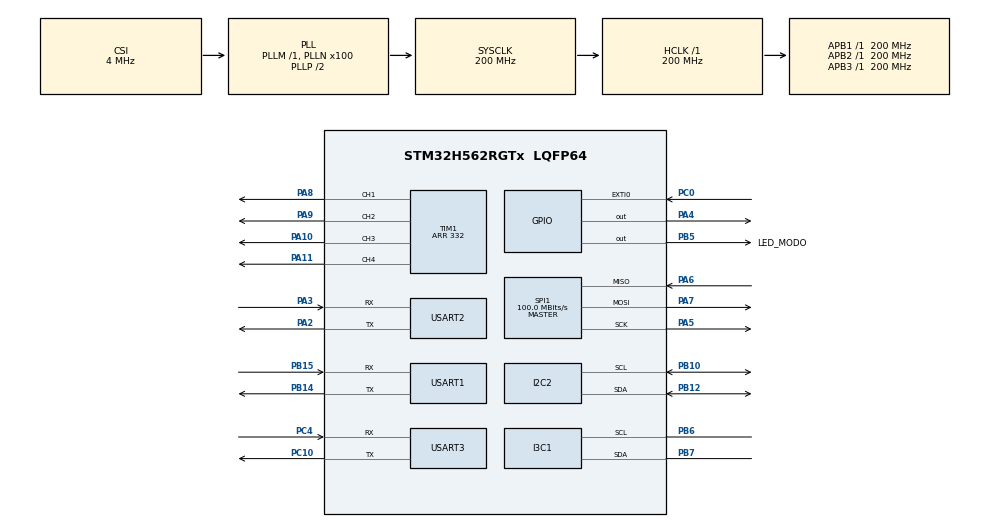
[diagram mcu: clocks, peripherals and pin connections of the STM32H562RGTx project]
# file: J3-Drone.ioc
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BOOTPATH.BootPathName=LEGACY
BOOTPATH.UserSelectedBootPath=LEGACY
CORTEX_M33_NS.Number-Cortex_Memory_Protection_Unit_Region0_OTP_RO_AREAS_Settings=MPU_REGION_NUMBER0
CORTEX_M33_NS.default_mode_Activation=1
CORTEX_M33_NS.userName=CORTEX_M33
I2C2.Timing=0x30C0EDFF
I3C1.BusFreeDuration=403
I3C1.Register0=0x005f3f5f
I3C1.Register1=0x002700c6
I3C1.SCLI3CHighDuration=0x3f
I3C1.SCLODLowDuration=0x5f
I3C1.SCLPPLowDuration=0x5f
I3C1.SCL_OD_Freq=1250
I3C1.SCL_PP_Freq=1250
I3C1.hexBusFreeDuration=0x27
I3C1.hexBusIdleDuration=0xc6
Mcu.Family=STM32H5
Mcu.Name=STM32H562RGTx
Mcu.Package=LQFP64
NVIC.EXTI0_IRQn=true\:5\:0\:false\:false\:true\:true\:false\:false
NVIC.PriorityGroup=NVIC_PRIORITYGROUP_4
NVIC.USART2_IRQn=true\:0\:0\:false\:false\:true\:true\:true\:true
PA10.Signal=S_TIM1_CH3
PA11.Signal=S_TIM1_CH4
PA13(JTMS/SWDIO).Mode=Serial_Wire
PA13(JTMS/SWDIO).Signal=DEBUG_JTMS-SWDIO
PA14(JTCK/SWCLK).Mode=Serial_Wire
PA14(JTCK/SWCLK).Signal=DEBUG_JTCK-SWCLK
PA2.Mode=Asynchronous
PA2.Signal=USART2_TX
PA3.Mode=Asynchronous
PA3.Signal=USART2_RX
PA4.Signal=GPIO_Output
PA5.Mode=Full_Duplex_Master
PA5.Signal=SPI1_SCK
PA6.Mode=Full_Duplex_Master
PA6.Signal=SPI1_MISO
PA7.Mode=Full_Duplex_Master
PA7.Signal=SPI1_MOSI
PA8.Signal=S_TIM1_CH1
PA9.Signal=S_TIM1_CH2
PB10.Mode=I2C
PB10.Signal=I2C2_SCL
PB12.Mode=I2C
PB12.Signal=I2C2_SDA
PB14.Mode=Asynchronous
PB14.Signal=USART1_TX
PB15.Mode=Asynchronous
PB15.Signal=USART1_RX
PB5.GPIO_Label=LED_MODO
PB5.Signal=GPIO_Output
PB6.Mode=Controller
PB6.Signal=I3C1_SCL
PB7.Mode=Controller
PB7.Signal=I3C1_SDA
PC0.Signal=GPXTI0
PC10.Mode=Asynchronous
PC10.Signal=USART3_TX
PC14-OSC32_IN(OSC32_IN).Mode=LSE-External-Oscillator
PC14-OSC32_IN(OSC32_IN).Signal=RCC_OSC32_IN
PC15-OSC32_OUT(OSC32_OUT).Mode=LSE-External-Oscillator
PC15-OSC32_OUT(OSC32_OUT).Signal=RCC_OSC32_OUT
PC4.Mode=Asynchronous
PC4.Signal=USART3_RX
PH0-OSC_IN(PH0).Mode=HSE-External-Oscillator
PH0-OSC_IN(PH0).Signal=RCC_OSC_IN
PH1-OSC_OUT(PH1).Mode=HSE-External-Oscillator
PH1-OSC_OUT(PH1).Signal=RCC_OSC_OUT
ProjectManager.HeapSize=0x200
ProjectManager.StackSize=0x400
ProjectManager.TargetToolchain=CMake
RCC.ADCFreq_Value=200000000
RCC.AHBFreq_Value=200000000
RCC.APB1Freq_Value=200000000
RCC.APB1TimFreq_Value=200000000
RCC.APB2Freq_Value=200000000
RCC.APB2TimFreq_Value=200000000
RCC.APB3Freq_Value=200000000
RCC.CSI_VALUE=4000000
RCC.CortexFreq_Value=200000000
RCC.EPOD_VALUE=4000000
RCC.HCLKFreq_Value=200000000
RCC.HSE_VALUE=25000000
RCC.HSI48_VALUE=48000000
RCC.HSI_VALUE=64000000
RCC.LSIRC_VALUE=32000
RCC.PLL2FRACN=0
RCC.PLL2M=1
RCC.PLL2N=96
RCC.PLL2P=8
RCC.PLL2Q=2
RCC.PLL2R=2
RCC.PLL2RGE=RCC_PLL2_VCIRANGE_2
RCC.PLL2State=RCC_PLL2_ON
RCC.PLL2VCOSEL=RCC_PLL2_VCORANGE_WIDE
RCC.PLL3FRACN=0
RCC.PLLFRACN=0
RCC.PLLN=100
RCC.SYSCLKFreq_VALUE=200000000
RCC.SYSCLKSource=RCC_SYSCLKSOURCE_PLLCLK
RCC.USBFreq_Value=48000000
RCC.VCOOutputFreq_Value=400000000
SH.S_TIM1_CH1.0=TIM1_CH1,PWM Generation1 CH1
SH.S_TIM1_CH2.0=TIM1_CH2,PWM Generation2 CH2
SH.S_TIM1_CH3.0=TIM1_CH3,PWM Generation3 CH3
SH.S_TIM1_CH4.0=TIM1_CH4,PWM Generation4 CH4
SPI1.BaudRatePrescaler=SPI_BAUDRATEPRESCALER_2
SPI1.CLKPhase=SPI_PHASE_1EDGE
SPI1.CLKPolarity=SPI_POLARITY_LOW
SPI1.CalculateBaudRate=100.0 MBits/s
SPI1.DataSize=SPI_DATASIZE_8BIT
SPI1.Direction=SPI_DIRECTION_2LINES
SPI1.FirstBit=SPI_FIRSTBIT_MSB
SPI1.Mode=SPI_MODE_MASTER
SPI1.NSS=SPI_NSS_SOFT
SPI1.NSSPMode=SPI_NSS_PULSE_DISABLE
SPI1.VirtualType=VM_MASTER
TIM1.Channel-PWM\ Generation1\ CH1=TIM_CHANNEL_1
TIM1.Channel-PWM\ Generation2\ CH2=TIM_CHANNEL_2
TIM1.Channel-PWM\ Generation3\ CH3=TIM_CHANNEL_3
TIM1.Channel-PWM\ Generation4\ CH4=TIM_CHANNEL_4
TIM1.PeriodNoDither=332
USART1.VirtualMode-Asynchronous=VM_ASYNC
USART2.VirtualMode-Asynchronous=VM_ASYNC
USART3.VirtualMode-Asynchronous=VM_ASYNC
VP_BOOTPATH_VS_BOOTPATH.Mode=BP_Activate
VP_CORTEX_M33_NS_VS_Hclk.Mode=Hclk_Mode
VP_GPDMA1_VS_GPDMACH2.Mode=SIMPLEREQUEST_GPDMACH2
VP_ICACHE_VS_ICACHE.Mode=DirectMappedCache
VP_MEMORYMAP_VS_MEMORYMAP.Mode=CurAppReg
VP_PWR_VS_LPOM.Mode=PowerOptimisation
VP_PWR_VS_SECSignals.Mode=Security/Privilege
VP_TIM1_VS_ClockSourceITR.Mode=TriggerSource_ITR1
VP_TIM1_VS_ControllerModeClock.Mode=Clock Mode
board=custom

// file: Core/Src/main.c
/* USER CODE BEGIN Header */
/**
  ******************************************************************************
  * @file           : main.c
  * @brief          : Main program body
  ******************************************************************************
  * @attention
  *
  * Copyright (c) 2026 STMicroelectronics.
  * All rights reserved.
  *
  * This software is licensed under terms that can be found in the LICENSE file
  * in the root directory of this software component.
  * If no LICENSE file comes with this software, it is provided AS-IS.
  *
  ******************************************************************************
  */
/* USER CODE END Header */
#include "main.h"
#include "gpdma.h"
#include "i2c.h"
#include "i3c.h"
#include "icache.h"
#include "spi.h"
#include "tim.h"
#include "usart.h"
#include "gpio.h"

/* USER CODE BEGIN Includes */
#include "usr/main_j3dronev2.h"
/* USER CODE END Includes */

void SystemClock_Config(void);
static void MPU_Config(void);

int main(void)
{

  /* MCU Configuration--------------------------------------------------------*/

  /* MPU Configuration--------------------------------------------------------*/
  MPU_Config();

  /* Reset of all peripherals, Initializes the Flash interface and the Systick. */
  HAL_Init();

  /* Configure the system clock */
  SystemClock_Config();

  /* Initialize all configured peripherals */
  MX_GPIO_Init();
  MX_GPDMA1_Init();
  MX_ICACHE_Init();
  MX_SPI1_Init();
  MX_USART2_UART_Init();
  MX_USART3_UART_Init();
  MX_I2C2_Init();
  MX_I3C1_Init();
  MX_USART1_UART_Init();
  MX_TIM1_Init();
  /* USER CODE BEGIN 2 */
  main_j3dronev2();
  /* USER CODE END 2 */

  /* Infinite loop */
  while (1)
  {

  }
}

void SystemClock_Config(void)
{
  RCC_OscInitTypeDef RCC_OscInitStruct = {0};
  RCC_ClkInitTypeDef RCC_ClkInitStruct = {0};

  /** Configure the main internal regulator output voltage
  */
  __HAL_PWR_VOLTAGESCALING_CONFIG(PWR_REGULATOR_VOLTAGE_SCALE1);

  while(!__HAL_PWR_GET_FLAG(PWR_FLAG_VOSRDY)) {}

  /** Initializes the RCC Oscillators according to the specified parameters
  * in the RCC_OscInitTypeDef structure.
  */
  RCC_OscInitStruct.OscillatorType = RCC_OSCILLATORTYPE_CSI;
  RCC_OscInitStruct.CSIState = RCC_CSI_ON;
  RCC_OscInitStruct.CSICalibrationValue = RCC_CSICALIBRATION_DEFAULT;
  RCC_OscInitStruct.PLL.PLLState = RCC_PLL_ON;
  RCC_OscInitStruct.PLL.PLLSource = RCC_PLL1_SOURCE_CSI;
  RCC_OscInitStruct.PLL.PLLM = 1;
  RCC_OscInitStruct.PLL.PLLN = 100;
  RCC_OscInitStruct.PLL.PLLP = 2;
  RCC_OscInitStruct.PLL.PLLQ = 2;
  RCC_OscInitStruct.PLL.PLLR = 2;
  RCC_OscInitStruct.PLL.PLLRGE = RCC_PLL1_VCIRANGE_2;
  RCC_OscInitStruct.PLL.PLLVCOSEL = RCC_PLL1_VCORANGE_WIDE;
  RCC_OscInitStruct.PLL.PLLFRACN = 0;
  if (HAL_RCC_OscConfig(&RCC_OscInitStruct) != HAL_OK)
  {
    Error_Handler();
  }

  /** Initializes the CPU, AHB and APB buses clocks
  */
  RCC_ClkInitStruct.ClockType = RCC_CLOCKTYPE_HCLK|RCC_CLOCKTYPE_SYSCLK
                              |RCC_CLOCKTYPE_PCLK1|RCC_CLOCKTYPE_PCLK2
                              |RCC_CLOCKTYPE_PCLK3;
  RCC_ClkInitStruct.SYSCLKSource = RCC_SYSCLKSOURCE_PLLCLK;
  RCC_ClkInitStruct.AHBCLKDivider = RCC_SYSCLK_DIV1;
  RCC_ClkInitStruct.APB1CLKDivider = RCC_HCLK_DIV1;
  RCC_ClkInitStruct.APB2CLKDivider = RCC_HCLK_DIV1;
  RCC_ClkInitStruct.APB3CLKDivider = RCC_HCLK_DIV1;

  if (HAL_RCC_ClockConfig(&RCC_ClkInitStruct, FLASH_LATENCY_5) != HAL_OK)
  {
    Error_Handler();
  }

  /** Configure the programming delay
  */
  __HAL_FLASH_SET_PROGRAM_DELAY(FLASH_PROGRAMMING_DELAY_2);
}

 /* MPU Configuration */

void MPU_Config(void)
{
  MPU_Region_InitTypeDef MPU_InitStruct = {0};
  MPU_Attributes_InitTypeDef MPU_AttributesInit = {0};

  /* Disables the MPU */
  HAL_MPU_Disable();

  /** Initializes and configures the Region 0 and the memory to be protected
  */
  MPU_InitStruct.Enable = MPU_REGION_ENABLE;
  MPU_InitStruct.Number = MPU_REGION_NUMBER0;
  MPU_InitStruct.BaseAddress = 0x08FFF000;
  MPU_InitStruct.LimitAddress = 0x08FFFFFF;
  MPU_InitStruct.AttributesIndex = MPU_ATTRIBUTES_NUMBER0;
  MPU_InitStruct.AccessPermission = MPU_REGION_ALL_RO;
  MPU_InitStruct.DisableExec = MPU_INSTRUCTION_ACCESS_DISABLE;
  MPU_InitStruct.IsShareable = MPU_ACCESS_NOT_SHAREABLE;

  HAL_MPU_ConfigRegion(&MPU_InitStruct);

  /** Initializes and configures the Attribute 0 and the memory to be protected
  */
  MPU_AttributesInit.Number = MPU_ATTRIBUTES_NUMBER0;
  MPU_AttributesInit.Attributes = INNER_OUTER(MPU_NOT_CACHEABLE);

  HAL_MPU_ConfigMemoryAttributes(&MPU_AttributesInit);
  /* Enables the MPU */
  HAL_MPU_Enable(MPU_PRIVILEGED_DEFAULT);

}

void Error_Handler(void)
{
  __disable_irq();
  while (1)
  {
  }
}
